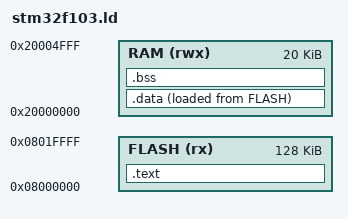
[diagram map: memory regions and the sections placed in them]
MEMORY
{
    FLASH (rx) : ORIGIN = 0x08000000, LENGTH = 128K
    RAM (rwx) : ORIGIN = 0x20000000, LENGTH = 20K
}

SECTIONS
{
    PROVIDE( _stack_ptr = ORIGIN(RAM) + LENGTH(RAM));

    /* constants  and other code stored in FLASH */
    .text :
    {
        _text = .;               /* beginning of .text segment,also called code memory */
        KEEP(*(.vector_table)) /* vector table defined in startup.c to be included */
        *(.text*)                   /* other code */
        *(.rodata*)                /* constants go here */
        _etext = .;             /* end of .text segment */
    } > FLASH

    /* data, initialized variables, to be copied to RAM upon <RESET> by startup.c */
    .data : 
    {
        _data = .;          /* beginning of .data segment */
        *(.data*)           /* data goes here */
        _edata = .;         /* end of .data segment */
    } > RAM AT >FLASH   /* .data segment starts directly after the .text section in FLASH */

    /* uninitialized data which is initialized to 0 upon <RESET> by startup.c */
    .bss :
    {
        _bss = .;       /* beginning of .bss segment */
        *(.bss*)        /* .bss content goes here */
        *(COMMON)       
        _ebss = .;      /* end of .bss segment */
    } > RAM
}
